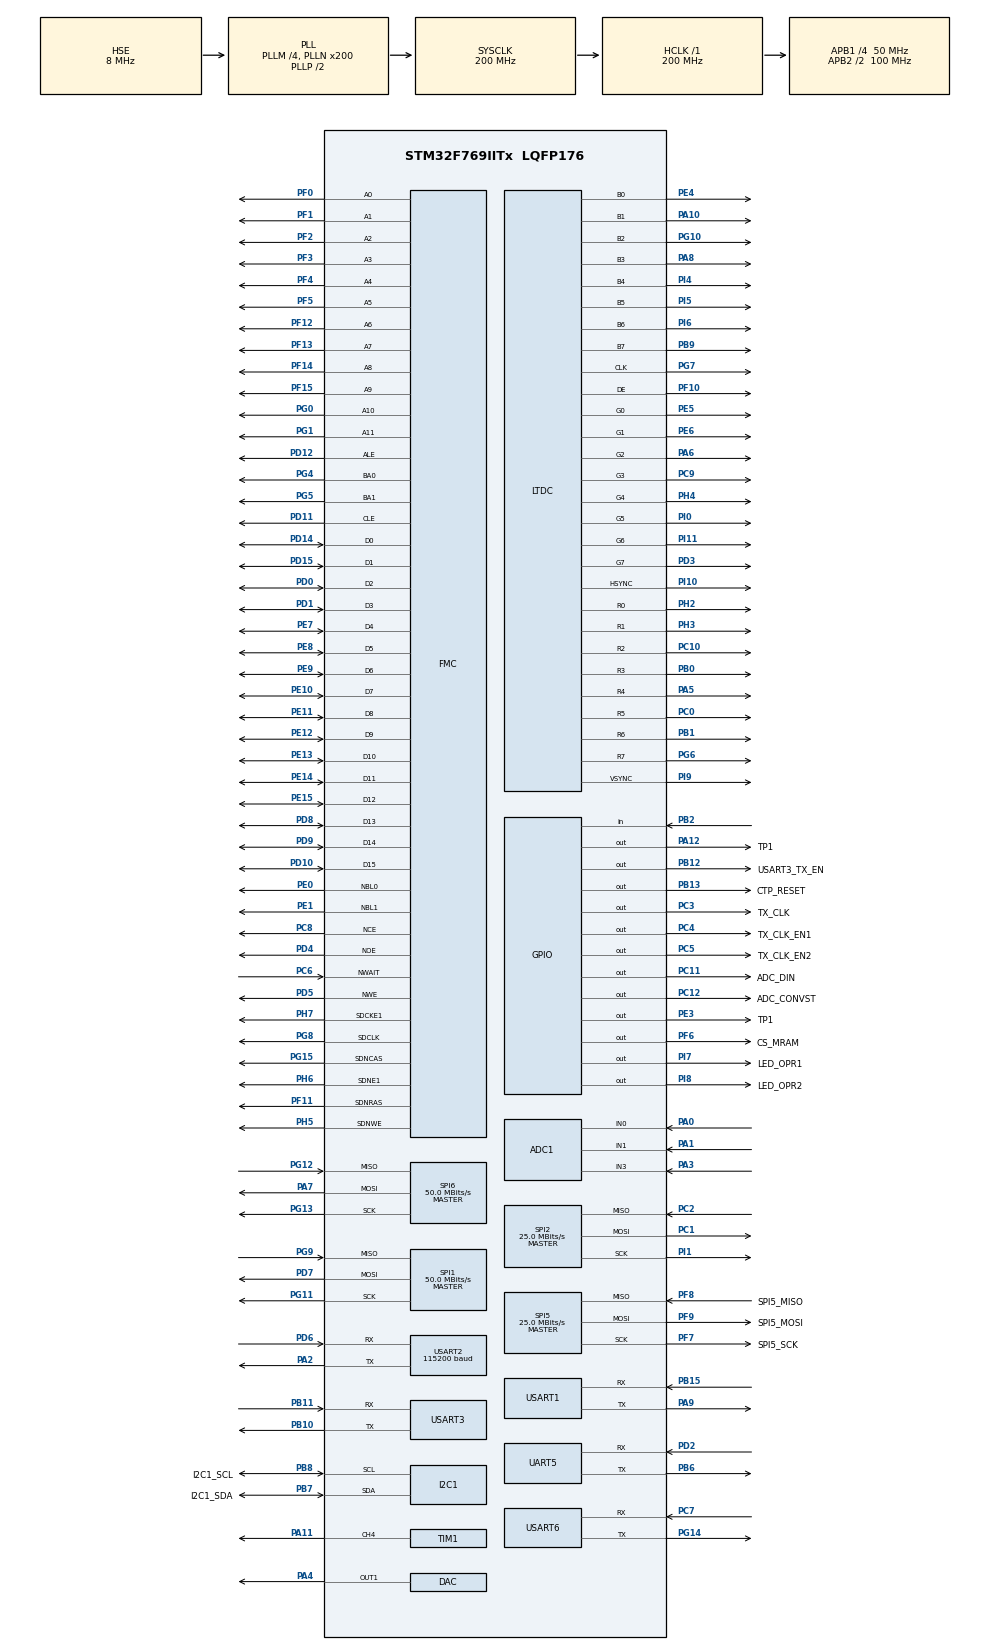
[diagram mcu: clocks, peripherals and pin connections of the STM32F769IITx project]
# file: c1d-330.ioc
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ADC1.Channel-0\#ChannelRegularConversion=ADC_CHANNEL_1
ADC1.DiscontinuousConvMode=DISABLE
ADC1.ExternalTrigConv=ADC_SOFTWARE_START
ADC1.NbrOfConversion=1
ADC1.NbrOfConversionFlag=1
ADC1.Rank-0\#ChannelRegularConversion=1
ADC1.SamplingTime-0\#ChannelRegularConversion=ADC_SAMPLETIME_3CYCLES
ADC1.ScanConvMode=ADC_SCAN_DISABLE
ADC1.master=1
DMA2D.ColorMode=DMA2D_OUTPUT_ARGB8888
Dma.MEMTOMEM.0.Direction=DMA_MEMORY_TO_MEMORY
Dma.MEMTOMEM.0.FIFOMode=DMA_FIFOMODE_ENABLE
Dma.MEMTOMEM.0.FIFOThreshold=DMA_FIFO_THRESHOLD_FULL
Dma.MEMTOMEM.0.Instance=DMA2_Stream0
Dma.MEMTOMEM.0.MemBurst=DMA_MBURST_SINGLE
Dma.MEMTOMEM.0.MemDataAlignment=DMA_MDATAALIGN_WORD
Dma.MEMTOMEM.0.MemInc=DMA_MINC_ENABLE
Dma.MEMTOMEM.0.Mode=DMA_NORMAL
Dma.MEMTOMEM.0.PeriphBurst=DMA_PBURST_SINGLE
Dma.MEMTOMEM.0.PeriphDataAlignment=DMA_PDATAALIGN_WORD
Dma.MEMTOMEM.0.PeriphInc=DMA_PINC_ENABLE
Dma.MEMTOMEM.0.Priority=DMA_PRIORITY_LOW
Dma.Request0=MEMTOMEM
FMC.AttributeSpaceHiZSetupTime1=2
FMC.AttributeSpaceHoldSetupTime1=4
FMC.AttributeSpaceSetupTime1=2
FMC.AttributeSpaceWaitSetupTime1=4
FMC.CASLatency1=FMC_SDRAM_CAS_LATENCY_3
FMC.ColumnBitsNumber1=FMC_SDRAM_COLUMN_BITS_NUM_9
FMC.CommonSpaceHiZSetupTime1=2
FMC.CommonSpaceHoldSetupTime1=4
FMC.CommonSpaceSetupTime1=2
FMC.CommonSpaceWaitSetupTime1=4
FMC.ECCPageSize1=FMC_NAND_ECC_PAGE_SIZE_512BYTE
FMC.EccComputation1=FMC_NAND_ECC_DISABLE
FMC.ExitSelfRefreshDelay1=7
FMC.LoadToActiveDelay1=2
FMC.NandBlockNbr1=512
FMC.NandBlockSize1=64
FMC.NandPageSize1=2048
FMC.NandPlaneNbr1=2
FMC.NandPlaneSize1=69206016
FMC.NandSpareAreaSize1=64
FMC.RCDDelay1=2
FMC.RPDelay1=2
FMC.ReadPipeDelay1=FMC_SDRAM_RPIPE_DELAY_1
FMC.RowCycleDelay1=6
FMC.SDClockPeriod1=FMC_SDRAM_CLOCK_PERIOD_2
FMC.SelfRefreshTime1=4
FMC.TARSetupTime1=2
FMC.TCLRSetupTime1=2
FMC.WriteRecoveryTime1=2
I2C1.Analog_Filter=I2C_ANALOGFILTER_ENABLE
I2C1.Timing=0x00C0EAFF
LTDC.ActiveH=480
LTDC.ActiveW=800
LTDC.Alpha_L0=0x00
LTDC.Alpha_L1=0x00
LTDC.BlendingFactor1_L0=LTDC_BLENDING_FACTOR1_PAxCA
LTDC.BlendingFactor1_L1=LTDC_BLENDING_FACTOR1_PAxCA
LTDC.BlendingFactor2_L0=LTDC_BLENDING_FACTOR2_PAxCA
LTDC.BlendingFactor2_L1=LTDC_BLENDING_FACTOR2_PAxCA
LTDC.DEPolarity=LTDC_DEPOLARITY_AL
LTDC.FBStartAdress_L0=0xD0000000
LTDC.FBStartAdress_L1=0xD0200000
LTDC.HBP=46
LTDC.HFP=210
LTDC.HSPolarity=LTDC_HSPOLARITY_AH
LTDC.HSync=20
LTDC.ImageHeight_L0=480
LTDC.ImageHeight_L1=480
LTDC.ImageWidth_L0=800
LTDC.ImageWidth_L1=800
LTDC.Layers=1
LTDC.PCPolarity=LTDC_PCPOLARITY_IIPC
LTDC.PixelFormat_L0=LTDC_PIXEL_FORMAT_ARGB8888
LTDC.PixelFormat_L1=LTDC_PIXEL_FORMAT_ARGB8888
LTDC.VBP=23
LTDC.VFP=22
LTDC.VSPolarity=LTDC_VSPOLARITY_AH
LTDC.VSync=10
LTDC.WindowX1_L0=800
LTDC.WindowX1_L1=800
LTDC.WindowY1_L0=480
LTDC.WindowY1_L1=480
Mcu.Family=STM32F7
Mcu.Name=STM32F769IITx
Mcu.Package=LQFP176
NVIC.PriorityGroup=NVIC_PRIORITYGROUP_4
NVIC.TIM2_IRQn=true\:0\:0\:false\:false\:true\:true\:true\:true
NVIC.TIM3_IRQn=true\:0\:0\:false\:false\:true\:true\:true\:true
NVIC.TIM4_IRQn=true\:0\:0\:false\:false\:true\:true\:true\:true
NVIC.TIM5_IRQn=true\:0\:0\:false\:false\:true\:true\:true\:true
NVIC.TIM6_DAC_IRQn=true\:0\:0\:false\:false\:true\:true\:true\:true
NVIC.TIM7_IRQn=true\:0\:0\:false\:false\:true\:true\:true\:true
NVIC.TIM8_TRG_COM_TIM14_IRQn=true\:0\:0\:false\:false\:true\:true\:true\:true
NVIC.TIM8_UP_TIM13_IRQn=true\:0\:0\:false\:false\:true\:true\:true\:true
NVIC.USART1_IRQn=true\:0\:0\:false\:false\:true\:true\:true\:true
NVIC.USART2_IRQn=true\:0\:0\:false\:false\:true\:true\:true\:true
NVIC.USART3_IRQn=true\:0\:0\:false\:false\:true\:true\:true\:true
PA0/WKUP.Signal=ADCx_IN0
PA1.Signal=ADCx_IN1
PA10.GPIO_Speed=GPIO_SPEED_FREQ_VERY_HIGH
PA10.Mode=RGB888
PA10.Signal=LTDC_B1
PA11.GPIO_Speed=GPIO_SPEED_FREQ_HIGH
PA11.Signal=S_TIM1_CH4
PA12.GPIO_Label=TP1
PA12.GPIO_Speed=GPIO_SPEED_FREQ_VERY_HIGH
PA12.Signal=GPIO_Output
PA13.Mode=JTAG_5_pins
PA13.Signal=SYS_JTMS-SWDIO
PA14.Mode=JTAG_5_pins
PA14.Signal=SYS_JTCK-SWCLK
PA15.Mode=JTAG_5_pins
PA15.Signal=SYS_JTDI
PA2.Mode=Asynchronous
PA2.Signal=USART2_TX
PA3.Signal=ADCx_IN3
PA4.Signal=COMP_DAC1_group
PA5.GPIO_Speed=GPIO_SPEED_FREQ_VERY_HIGH
PA5.Mode=RGB888
PA5.Signal=LTDC_R4
PA6.GPIO_Speed=GPIO_SPEED_FREQ_VERY_HIGH
PA6.Mode=RGB888
PA6.Signal=LTDC_G2
PA7.Mode=Full_Duplex_Master
PA7.Signal=SPI6_MOSI
PA8.GPIO_Speed=GPIO_SPEED_FREQ_VERY_HIGH
PA8.Mode=RGB888
PA8.Signal=LTDC_B3
PA9.Mode=Asynchronous
PA9.Signal=USART1_TX
PB0.GPIO_Speed=GPIO_SPEED_FREQ_VERY_HIGH
PB0.Mode=RGB888
PB0.Signal=LTDC_R3
PB1.GPIO_Speed=GPIO_SPEED_FREQ_VERY_HIGH
PB1.Mode=RGB888
PB1.Signal=LTDC_R6
PB10.Mode=Asynchronous
PB10.Signal=USART3_TX
PB11.Mode=Asynchronous
PB11.Signal=USART3_RX
PB12.GPIO_Label=USART3_TX_EN
PB12.GPIO_Speed=GPIO_SPEED_FREQ_HIGH
PB12.Signal=GPIO_Output
PB13.GPIO_Label=CTP_RESET
PB13.GPIO_Speed=GPIO_SPEED_FREQ_HIGH
PB13.Signal=GPIO_Output
PB15.Mode=Asynchronous
PB15.Signal=USART1_RX
PB2.Signal=GPIO_Input
PB3.Mode=JTAG_5_pins
PB3.Signal=SYS_JTDO-SWO
PB4.Mode=JTAG_5_pins
PB4.Signal=SYS_JTRST
PB6.Mode=Asynchronous
PB6.Signal=UART5_TX
PB7.GPIO_Label=I2C1_SDA
PB7.Mode=I2C
PB7.Signal=I2C1_SDA
PB8.GPIO_Label=I2C1_SCL
PB8.Mode=I2C
PB8.Signal=I2C1_SCL
PB9.GPIO_FM9=SYSCFG_PMC_I2C_PB9_FMP
PB9.GPIO_Speed=GPIO_SPEED_FREQ_VERY_HIGH
PB9.Mode=RGB888
PB9.Signal=LTDC_B7
PC0.GPIO_Speed=GPIO_SPEED_FREQ_VERY_HIGH
PC0.Mode=RGB888
PC0.Signal=LTDC_R5
PC1.Mode=Full_Duplex_Master
PC1.Signal=SPI2_MOSI
PC10.GPIO_Speed=GPIO_SPEED_FREQ_VERY_HIGH
PC10.Mode=RGB888
PC10.Signal=LTDC_R2
PC11.GPIO_Label=ADC_DIN
PC11.GPIO_Speed=GPIO_SPEED_FREQ_VERY_HIGH
PC11.PinState=GPIO_PIN_SET
PC11.Signal=GPIO_Output
PC12.GPIO_Label=ADC_CONVST
PC12.GPIO_Speed=GPIO_SPEED_FREQ_VERY_HIGH
PC12.PinState=GPIO_PIN_RESET
PC12.Signal=GPIO_Output
PC14/OSC32_IN.Mode=LSE-External-Oscillator
PC14/OSC32_IN.Signal=RCC_OSC32_IN
PC15/OSC32_OUT.Mode=LSE-External-Oscillator
PC15/OSC32_OUT.Signal=RCC_OSC32_OUT
PC2.Mode=Full_Duplex_Master
PC2.Signal=SPI2_MISO
PC3.GPIO_Label=TX_CLK
PC3.GPIO_Speed=GPIO_SPEED_FREQ_VERY_HIGH
PC3.Signal=GPIO_Output
PC4.GPIO_Label=TX_CLK_EN1
PC4.GPIO_Speed=GPIO_SPEED_FREQ_VERY_HIGH
PC4.Signal=GPIO_Output
PC5.GPIO_Label=TX_CLK_EN2
PC5.GPIO_Speed=GPIO_SPEED_FREQ_VERY_HIGH
PC5.Signal=GPIO_Output
PC6.Signal=FMC_NWAIT
PC7.Mode=Asynchronous
PC7.Signal=USART6_RX
PC8.Mode=NandChipSelect3_1
PC8.Signal=FMC_NCE
PC9.GPIO_Speed=GPIO_SPEED_FREQ_VERY_HIGH
PC9.Mode=RGB888
PC9.Signal=LTDC_G3
PD0.Signal=FMC_D2_DA2
PD1.Signal=FMC_D3_DA3
PD10.Signal=FMC_D15_DA15
PD11.Signal=FMC_A16_CLE
PD12.Signal=FMC_A17_ALE
PD14.Signal=FMC_D0_DA0
PD15.Signal=FMC_D1_DA1
PD2.Mode=Asynchronous
PD2.Signal=UART5_RX
PD3.GPIO_Speed=GPIO_SPEED_FREQ_VERY_HIGH
PD3.Mode=RGB888
PD3.Signal=LTDC_G7
PD4.Signal=FMC_NOE
PD5.Signal=FMC_NWE
PD6.Mode=Asynchronous
PD6.Signal=USART2_RX
PD7.Mode=Full_Duplex_Master
PD7.Signal=SPI1_MOSI
PD8.Signal=FMC_D13_DA13
PD9.Signal=FMC_D14_DA14
PE0.Signal=FMC_NBL0
PE1.Signal=FMC_NBL1
PE10.Signal=FMC_D7_DA7
PE11.Signal=FMC_D8_DA8
PE12.Signal=FMC_D9_DA9
PE13.Signal=FMC_D10_DA10
PE14.Signal=FMC_D11_DA11
PE15.Signal=FMC_D12_DA12
PE3.GPIO_Label=TP1
PE3.Signal=GPIO_Output
PE4.GPIO_Speed=GPIO_SPEED_FREQ_VERY_HIGH
PE4.Mode=RGB888
PE4.Signal=LTDC_B0
PE5.GPIO_Speed=GPIO_SPEED_FREQ_VERY_HIGH
PE5.Mode=RGB888
PE5.Signal=LTDC_G0
PE6.GPIO_Speed=GPIO_SPEED_FREQ_VERY_HIGH
PE6.Mode=RGB888
PE6.Signal=LTDC_G1
PE7.Signal=FMC_D4_DA4
PE8.Signal=FMC_D5_DA5
PE9.Signal=FMC_D6_DA6
PF0.Signal=FMC_A0
PF1.Signal=FMC_A1
PF10.GPIO_Speed=GPIO_SPEED_FREQ_VERY_HIGH
PF10.Mode=RGB888
PF10.Signal=LTDC_DE
PF11.Signal=FMC_SDNRAS
PF12.Signal=FMC_A6
PF13.Signal=FMC_A7
PF14.Signal=FMC_A8
PF15.Signal=FMC_A9
PF2.Signal=FMC_A2
PF3.Signal=FMC_A3
PF4.Signal=FMC_A4
PF5.Signal=FMC_A5
PF6.GPIO_Label=CS_MRAM
PF6.GPIO_Speed=GPIO_SPEED_FREQ_VERY_HIGH
PF6.PinState=GPIO_PIN_SET
PF6.Signal=GPIO_Output
PF7.GPIO_Label=SPI5_SCK
PF7.GPIO_PuPd=GPIO_NOPULL
PF7.GPIO_Speed=GPIO_SPEED_FREQ_MEDIUM
PF7.Mode=Full_Duplex_Master
PF7.Signal=SPI5_SCK
PF8.GPIO_Label=SPI5_MISO
PF8.GPIO_PuPd=GPIO_NOPULL
PF8.GPIO_Speed=GPIO_SPEED_FREQ_MEDIUM
PF8.Mode=Full_Duplex_Master
PF8.Signal=SPI5_MISO
PF9.GPIO_Label=SPI5_MOSI
PF9.GPIO_Speed=GPIO_SPEED_FREQ_MEDIUM
PF9.Mode=Full_Duplex_Master
PF9.Signal=SPI5_MOSI
PG0.Signal=FMC_A10
PG1.Signal=FMC_A11
PG10.GPIO_Speed=GPIO_SPEED_FREQ_VERY_HIGH
PG10.Mode=RGB888
PG10.Signal=LTDC_B2
PG11.Mode=Full_Duplex_Master
PG11.Signal=SPI1_SCK
PG12.Mode=Full_Duplex_Master
PG12.Signal=SPI6_MISO
PG13.Mode=Full_Duplex_Master
PG13.Signal=SPI6_SCK
PG14.Mode=Asynchronous
PG14.Signal=USART6_TX
PG15.Signal=FMC_SDNCAS
PG4.Signal=FMC_A14_BA0
PG5.Signal=FMC_A15_BA1
PG6.GPIO_Speed=GPIO_SPEED_FREQ_VERY_HIGH
PG6.Mode=RGB888
PG6.Signal=LTDC_R7
PG7.GPIO_Speed=GPIO_SPEED_FREQ_VERY_HIGH
PG7.Mode=RGB888
PG7.Signal=LTDC_CLK
PG8.Signal=FMC_SDCLK
PG9.Mode=Full_Duplex_Master
PG9.Signal=SPI1_MISO
PH0/OSC_IN.Mode=HSE-External-Oscillator
PH0/OSC_IN.Signal=RCC_OSC_IN
PH1/OSC_OUT.Mode=HSE-External-Oscillator
PH1/OSC_OUT.Signal=RCC_OSC_OUT
PH2.GPIO_Speed=GPIO_SPEED_FREQ_VERY_HIGH
PH2.Mode=RGB888
PH2.Signal=LTDC_R0
PH3.GPIO_Speed=GPIO_SPEED_FREQ_VERY_HIGH
PH3.Mode=RGB888
PH3.Signal=LTDC_R1
PH4.GPIO_Speed=GPIO_SPEED_FREQ_VERY_HIGH
PH4.Mode=RGB888
PH4.Signal=LTDC_G4
PH5.Signal=FMC_SDNWE
PH6.Mode=SdramChipSelect2_1
PH6.Signal=FMC_SDNE1
PH7.Mode=SdramChipSelect2_1
PH7.Signal=FMC_SDCKE1
PI0.GPIO_Speed=GPIO_SPEED_FREQ_VERY_HIGH
PI0.Mode=RGB888
PI0.Signal=LTDC_G5
PI1.Mode=Full_Duplex_Master
PI1.Signal=SPI2_SCK
PI10.GPIO_Speed=GPIO_SPEED_FREQ_VERY_HIGH
PI10.Mode=RGB888
PI10.Signal=LTDC_HSYNC
PI11.GPIO_Speed=GPIO_SPEED_FREQ_VERY_HIGH
PI11.Mode=RGB888
PI11.Signal=LTDC_G6
PI4.GPIO_Speed=GPIO_SPEED_FREQ_VERY_HIGH
PI4.Mode=RGB888
PI4.Signal=LTDC_B4
PI5.GPIO_Speed=GPIO_SPEED_FREQ_VERY_HIGH
PI5.Mode=RGB888
PI5.Signal=LTDC_B5
PI6.GPIO_FM8=SYSCFG_PMC_I2C_PB8_FMP
PI6.GPIO_Speed=GPIO_SPEED_FREQ_VERY_HIGH
PI6.Mode=RGB888
PI6.Signal=LTDC_B6
PI7.GPIO_Label=LED_OPR1
PI7.GPIO_Speed=GPIO_SPEED_FREQ_LOW
PI7.Signal=GPIO_Output
PI8.GPIO_Label=LED_OPR2
PI8.Signal=GPIO_Output
PI9.GPIO_Speed=GPIO_SPEED_FREQ_VERY_HIGH
PI9.Mode=RGB888
PI9.Signal=LTDC_VSYNC
ProjectManager.HeapSize=0x200
ProjectManager.StackSize=0x400
ProjectManager.TargetToolchain=STM32CubeIDE
RCC.AHBFreq_Value=200000000
RCC.APB1CLKDivider=RCC_HCLK_DIV4
RCC.APB1Freq_Value=50000000
RCC.APB1TimFreq_Value=100000000
RCC.APB2CLKDivider=RCC_HCLK_DIV2
RCC.APB2Freq_Value=100000000
RCC.APB2TimFreq_Value=200000000
RCC.CortexFreq_Value=200000000
RCC.HCLKFreq_Value=200000000
RCC.HSE_VALUE=8000000
RCC.HSI_VALUE=16000000
RCC.PLLM=4
RCC.PLLN=200
RCC.PLLSAIN=96
RCC.PLLSAIRDiv=RCC_PLLSAIDIVR_4
RCC.PLLSourceVirtual=RCC_PLLSOURCE_HSE
RCC.RTCClockSelection=RCC_RTCCLKSOURCE_LSE
RCC.SYSCLKFreq_VALUE=200000000
RCC.SYSCLKSource=RCC_SYSCLKSOURCE_PLLCLK
RCC.USBFreq_Value=200000000
RCC.VCOOutputFreq_Value=400000000
SH.ADCx_IN0.0=ADC1_IN0,IN0
SH.ADCx_IN1.0=ADC1_IN1,IN1
SH.ADCx_IN3.0=ADC1_IN3,IN3
SH.COMP_DAC1_group.0=DAC_OUT1,DAC_OUT1
SH.FMC_A0.0=FMC_A0,12b-sda1
SH.FMC_A1.0=FMC_A1,12b-sda1
SH.FMC_A10.0=FMC_A10,12b-sda1
SH.FMC_A11.0=FMC_A11,12b-sda1
SH.FMC_A14_BA0.0=FMC_BA0,FourSdramBanks1
SH.FMC_A15_BA1.0=FMC_BA1,FourSdramBanks1
SH.FMC_A16_CLE.0=FMC_CLE,8b-dmux1
SH.FMC_A17_ALE.0=FMC_ALE,8b-dmux1
SH.FMC_A2.0=FMC_A2,12b-sda1
SH.FMC_A3.0=FMC_A3,12b-sda1
SH.FMC_A4.0=FMC_A4,12b-sda1
SH.FMC_A5.0=FMC_A5,12b-sda1
SH.FMC_A6.0=FMC_A6,12b-sda1
SH.FMC_A7.0=FMC_A7,12b-sda1
SH.FMC_A8.0=FMC_A8,12b-sda1
SH.FMC_A9.0=FMC_A9,12b-sda1
SH.FMC_D0_DA0.0=FMC_D0,sd-16b-d1
SH.FMC_D0_DA0.1=FMC_D0,8b-dmux1
SH.FMC_D10_DA10.0=FMC_D10,sd-16b-d1
SH.FMC_D11_DA11.0=FMC_D11,sd-16b-d1
SH.FMC_D12_DA12.0=FMC_D12,sd-16b-d1
SH.FMC_D13_DA13.0=FMC_D13,sd-16b-d1
SH.FMC_D14_DA14.0=FMC_D14,sd-16b-d1
SH.FMC_D15_DA15.0=FMC_D15,sd-16b-d1
SH.FMC_D1_DA1.0=FMC_D1,sd-16b-d1
SH.FMC_D1_DA1.1=FMC_D1,8b-dmux1
SH.FMC_D2_DA2.0=FMC_D2,sd-16b-d1
SH.FMC_D2_DA2.1=FMC_D2,8b-dmux1
SH.FMC_D3_DA3.0=FMC_D3,sd-16b-d1
SH.FMC_D3_DA3.1=FMC_D3,8b-dmux1
SH.FMC_D4_DA4.0=FMC_D4,sd-16b-d1
SH.FMC_D4_DA4.1=FMC_D4,8b-dmux1
SH.FMC_D5_DA5.0=FMC_D5,sd-16b-d1
SH.FMC_D5_DA5.1=FMC_D5,8b-dmux1
SH.FMC_D6_DA6.0=FMC_D6,sd-16b-d1
SH.FMC_D6_DA6.1=FMC_D6,8b-dmux1
SH.FMC_D7_DA7.0=FMC_D7,sd-16b-d1
SH.FMC_D7_DA7.1=FMC_D7,8b-dmux1
SH.FMC_D8_DA8.0=FMC_D8,sd-16b-d1
SH.FMC_D9_DA9.0=FMC_D9,sd-16b-d1
SH.FMC_NBL0.0=FMC_NBL0,Sd2ByteEnable1
SH.FMC_NBL1.0=FMC_NBL1,Sd2ByteEnable1
SH.FMC_NOE.0=FMC_NOE,8b-dmux1
SH.FMC_NWAIT.0=FMC_NWAIT,Wait1
SH.FMC_NWE.0=FMC_NWE,8b-dmux1
SH.FMC_SDCLK.0=FMC_SDCLK,12b-sda1
SH.FMC_SDNCAS.0=FMC_SDNCAS,12b-sda1
SH.FMC_SDNRAS.0=FMC_SDNRAS,12b-sda1
SH.FMC_SDNWE.0=FMC_SDNWE,12b-sda1
SH.S_TIM1_CH4.0=TIM1_CH4,PWM Generation4 CH4
SPI1.CalculateBaudRate=50.0 MBits/s
SPI1.Direction=SPI_DIRECTION_2LINES
SPI1.Mode=SPI_MODE_MASTER
SPI1.VirtualType=VM_MASTER
SPI2.CalculateBaudRate=25.0 MBits/s
SPI2.Direction=SPI_DIRECTION_2LINES
SPI2.Mode=SPI_MODE_MASTER
SPI2.VirtualType=VM_MASTER
SPI5.BaudRatePrescaler=SPI_BAUDRATEPRESCALER_4
SPI5.CLKPhase=SPI_PHASE_1EDGE
SPI5.CalculateBaudRate=25.0 MBits/s
SPI5.DataSize=SPI_DATASIZE_8BIT
SPI5.Direction=SPI_DIRECTION_2LINES
SPI5.Mode=SPI_MODE_MASTER
SPI5.NSSPMode=SPI_NSS_PULSE_DISABLE
SPI5.VirtualType=VM_MASTER
SPI6.CalculateBaudRate=50.0 MBits/s
SPI6.Direction=SPI_DIRECTION_2LINES
SPI6.Mode=SPI_MODE_MASTER
SPI6.VirtualType=VM_MASTER
TIM1.Channel-PWM\ Generation4\ CH4=TIM_CHANNEL_4
TIM1.OCMode_PWM-PWM\ Generation4\ CH4=TIM_OCMODE_PWM1
TIM1.OCPolarity_4=TIM_OCPOLARITY_LOW
TIM1.Period=74-1
TIM1.Prescaler=17-1
TIM1.Pulse-PWM\ Generation4\ CH4=37
TIM1.RepetitionCounter=0
TIM1.TIM_MasterOutputTrigger=TIM_TRGO_UPDATE
TIM1.TIM_MasterSlaveMode=TIM_MASTERSLAVEMODE_ENABLE
TIM14.Period=10000-1
TIM14.Prescaler=10000-1
TIM2.Period=10-1
TIM2.Prescaler=10000-1
TIM3.Period=100-1
TIM3.Prescaler=10000-1
TIM4.Period=500-1
TIM4.Prescaler=10000-1
TIM5.Period=1000-1
TIM5.Prescaler=10000-1
TIM6.Period=2-1
TIM6.Prescaler=675-1
TIM7.Period=5000-1
TIM7.Prescaler=10000-1
TIM8.Period=1
USART1.VirtualMode-Asynchronous=VM_ASYNC
USART2.BaudRate=115200
USART2.Parity=PARITY_NONE
USART2.VirtualMode-Asynchronous=VM_ASYNC
USART2.WordLength=WORDLENGTH_8B
USART3.VirtualMode-Asynchronous=VM_ASYNC
USART6.VirtualMode-Asynchronous=VM_ASYNC
VP_DMA2D_VS_DMA2D.Mode=DMA2D_Activate
VP_RTC_VS_RTC_Activate.Mode=RTC_Enabled
VP_TIM14_VS_ClockSourceINT.Mode=Enable_Timer
VP_TIM1_VS_ClockSourceINT.Mode=Internal
VP_TIM2_VS_ClockSourceINT.Mode=Internal
VP_TIM3_VS_ClockSourceINT.Mode=Internal
VP_TIM4_VS_ClockSourceINT.Mode=Internal
VP_TIM5_VS_ClockSourceINT.Mode=Internal
VP_TIM6_VS_ClockSourceINT.Mode=Enable_Timer
VP_TIM7_VS_ClockSourceINT.Mode=Enable_Timer
VP_TIM8_VS_ClockSourceITR.Mode=TriggerSource_ITR0
VP_TIM8_VS_ControllerModeClock.Mode=Clock Mode
board=custom

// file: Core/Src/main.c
/* USER CODE BEGIN Header */
/**
  ******************************************************************************
  * @file           : main.c
  * @brief          : Main program body
  ******************************************************************************
  * @attention
  *
  * <h2><center>&copy; Copyright (c) 2021 STMicroelectronics.
  * All rights reserved.</center></h2>
  *
  * This software component is licensed by ST under BSD 3-Clause license,
  * the "License"; You may not use this file except in compliance with the
  * License. You may obtain a copy of the License at:
  *                        opensource.org/licenses/BSD-3-Clause
  *
  ******************************************************************************
  */
/* USER CODE END Header */
#include "main.h"
#include "adc.h"
#include "dac.h"
#include "dma.h"
#include "dma2d.h"
#include "i2c.h"
#include "ltdc.h"
#include "rtc.h"
#include "spi.h"
#include "tim.h"
#include "usart.h"
#include "gpio.h"
#include "fmc.h"

/* USER CODE BEGIN Includes */
// std
#include <stdio.h>
#include "dbg_main.h"
#include "bsp_main.h"
#include "app_main.h"

// app
#include "app_string.h"
// bsp
#include "bsp_lcd.h"
#include "bsp_gpio.h"
#include "bsp_nand.h"
#include "bsp_ram.h"

/* USER CODE END Includes */

void SystemClock_Config(void);

int main(void)
{

  /* MCU Configuration--------------------------------------------------------*/

  /* Reset of all peripherals, Initializes the Flash interface and the Systick. */
  HAL_Init();

  /* Configure the system clock */
  SystemClock_Config();

  /* Initialize all configured peripherals */
  MX_GPIO_Init();
  MX_FMC_Init();
  MX_LTDC_Init();
  MX_RTC_Init();
  MX_SPI5_Init();
  MX_TIM14_Init();
  MX_USART1_UART_Init();
  MX_USART2_UART_Init();
  MX_USART3_UART_Init();
  MX_ADC1_Init();
  MX_DAC_Init();
  MX_USART6_UART_Init();
  MX_I2C1_Init();
  MX_DMA2D_Init();
  MX_SPI1_Init();
  MX_SPI2_Init();
  MX_SPI6_Init();
  MX_DMA_Init();
  MX_UART5_Init();
  MX_TIM2_Init();
  MX_TIM3_Init();
  MX_TIM4_Init();
  MX_TIM5_Init();
  MX_TIM6_Init();
  MX_TIM1_Init();
  MX_TIM7_Init();
  MX_TIM8_Init();
  /* USER CODE BEGIN 2 */
	SCB->VTOR = 0x08008000;
	__enable_irq();

	BSP_InitMain();
	APP_InitMain();

#if defined (_DBG_LOOP_EN_)
	DBG_InitVari();
#endif

  /* USER CODE END 2 */

  /* Infinite loop */
	while (1)
	{

    /* USER CODE BEGIN 3 */
#if defined (_DBG_LOOP_EN_)
	DBG_LoopMain();
#else
	APP_LoopMain();
#endif
	}
  /* USER CODE END 3 */
}

void SystemClock_Config(void)
{
  RCC_OscInitTypeDef RCC_OscInitStruct = {0};
  RCC_ClkInitTypeDef RCC_ClkInitStruct = {0};

  /** Configure LSE Drive Capability
  */
  HAL_PWR_EnableBkUpAccess();
  __HAL_RCC_LSEDRIVE_CONFIG(RCC_LSEDRIVE_LOW);
  /** Configure the main internal regulator output voltage
  */
  __HAL_RCC_PWR_CLK_ENABLE();
  __HAL_PWR_VOLTAGESCALING_CONFIG(PWR_REGULATOR_VOLTAGE_SCALE1);
  /** Initializes the RCC Oscillators according to the specified parameters
  * in the RCC_OscInitTypeDef structure.
  */
  RCC_OscInitStruct.OscillatorType = RCC_OSCILLATORTYPE_HSE|RCC_OSCILLATORTYPE_LSE;
  RCC_OscInitStruct.HSEState = RCC_HSE_ON;
  RCC_OscInitStruct.LSEState = RCC_LSE_ON;
  RCC_OscInitStruct.PLL.PLLState = RCC_PLL_ON;
  RCC_OscInitStruct.PLL.PLLSource = RCC_PLLSOURCE_HSE;
  RCC_OscInitStruct.PLL.PLLM = 4;
  RCC_OscInitStruct.PLL.PLLN = 200;
  RCC_OscInitStruct.PLL.PLLP = RCC_PLLP_DIV2;
  RCC_OscInitStruct.PLL.PLLQ = 2;
  RCC_OscInitStruct.PLL.PLLR = 2;
  if (HAL_RCC_OscConfig(&RCC_OscInitStruct) != HAL_OK)
  {
    Error_Handler();
  }
  /** Activate the Over-Drive mode
  */
  if (HAL_PWREx_EnableOverDrive() != HAL_OK)
  {
    Error_Handler();
  }
  /** Initializes the CPU, AHB and APB buses clocks
  */
  RCC_ClkInitStruct.ClockType = RCC_CLOCKTYPE_HCLK|RCC_CLOCKTYPE_SYSCLK
                              |RCC_CLOCKTYPE_PCLK1|RCC_CLOCKTYPE_PCLK2;
  RCC_ClkInitStruct.SYSCLKSource = RCC_SYSCLKSOURCE_PLLCLK;
  RCC_ClkInitStruct.AHBCLKDivider = RCC_SYSCLK_DIV1;
  RCC_ClkInitStruct.APB1CLKDivider = RCC_HCLK_DIV4;
  RCC_ClkInitStruct.APB2CLKDivider = RCC_HCLK_DIV2;

  if (HAL_RCC_ClockConfig(&RCC_ClkInitStruct, FLASH_LATENCY_6) != HAL_OK)
  {
    Error_Handler();
  }
}

void Error_Handler(void)
{
  __disable_irq();
  while (1)
  {
  }
}
